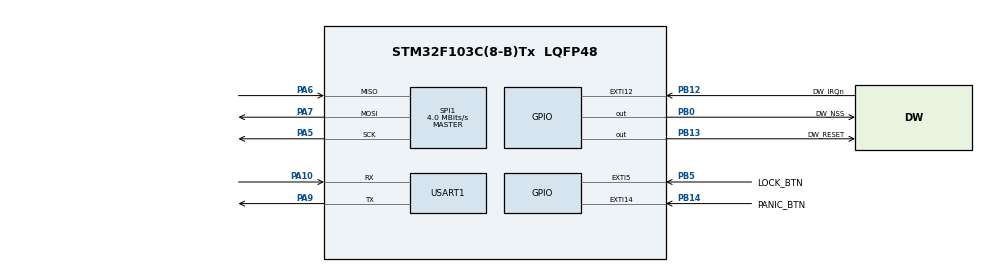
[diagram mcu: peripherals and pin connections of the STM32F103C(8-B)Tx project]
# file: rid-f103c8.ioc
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Mcu.Family=STM32F1
Mcu.Name=STM32F103C(8-B)Tx
Mcu.Package=LQFP48
NVIC.EXTI15_10_IRQn=true\:0\:0\:false\:false\:true\:true\:true\:true
NVIC.EXTI9_5_IRQn=true\:0\:0\:false\:false\:true\:true\:true\:true
NVIC.PriorityGroup=NVIC_PRIORITYGROUP_4
PA10.Mode=Asynchronous
PA10.Signal=USART1_RX
PA13.Mode=Serial_Wire
PA13.Signal=SYS_JTMS-SWDIO
PA14.Mode=Serial_Wire
PA14.Signal=SYS_JTCK-SWCLK
PA5.Mode=Full_Duplex_Master
PA5.Signal=SPI1_SCK
PA6.Mode=Full_Duplex_Master
PA6.Signal=SPI1_MISO
PA7.Mode=Full_Duplex_Master
PA7.Signal=SPI1_MOSI
PA9.Mode=Asynchronous
PA9.Signal=USART1_TX
PB0.GPIO_Label=DW_NSS
PB0.PinState=GPIO_PIN_SET
PB0.Signal=GPIO_Output
PB12.GPIO_Label=DW_IRQn
PB12.GPIO_PuPd=GPIO_PULLDOWN
PB12.Signal=GPXTI12
PB13.GPIO_Label=DW_RESET
PB13.GPIO_ModeDefaultOutputPP=GPIO_MODE_OUTPUT_OD
PB13.GPIO_PuPd=GPIO_NOPULL
PB13.Signal=GPIO_Output
PB14.GPIO_Label=PANIC_BTN
PB14.GPIO_ModeDefaultEXTI=GPIO_MODE_IT_FALLING
PB14.GPIO_PuPd=GPIO_PULLUP
PB14.Signal=GPXTI14
PB5.GPIO_Label=LOCK_BTN
PB5.GPIO_ModeDefaultEXTI=GPIO_MODE_IT_FALLING
PB5.GPIO_PuPd=GPIO_PULLUP
PB5.Signal=GPXTI5
ProjectManager.HeapSize=0x200
ProjectManager.StackSize=0x400
ProjectManager.TargetToolchain=STM32CubeIDE
RCC.APB1Freq_Value=8000000
RCC.APB2Freq_Value=8000000
SPI1.CalculateBaudRate=4.0 MBits/s
SPI1.Direction=SPI_DIRECTION_2LINES
SPI1.Mode=SPI_MODE_MASTER
SPI1.VirtualType=VM_MASTER
USART1.VirtualMode=VM_ASYNC
board=custom

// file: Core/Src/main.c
/* USER CODE BEGIN Header */
/**
  ******************************************************************************
  * @file           : main.c
  * @brief          : Main program body
  ******************************************************************************
  * @attention
  *
  * Copyright (c) 2022 STMicroelectronics.
  * All rights reserved.
  *
  * This software is licensed under terms that can be found in the LICENSE file
  * in the root directory of this software component.
  * If no LICENSE file comes with this software, it is provided AS-IS.
  *
  ******************************************************************************
  */
/* USER CODE END Header */
#include "main.h"

/* USER CODE BEGIN Includes */
#include "stdio_d.h"
#include "rid.h"

#include "deca_device_api.h"

//#include "ex_01a_simple_tx/ex_01a_main.c"
/* USER CODE END Includes */

SPI_HandleTypeDef hspi1;

UART_HandleTypeDef huart1;

void SystemClock_Config(void);
static void MX_GPIO_Init(void);
static void MX_SPI1_Init(void);
static void MX_USART1_UART_Init(void);

int main(void)
{

  /* MCU Configuration--------------------------------------------------------*/

  /* Reset of all peripherals, Initializes the Flash interface and the Systick. */
  HAL_Init();

  /* Configure the system clock */
  SystemClock_Config();

  /* Initialize all configured peripherals */
  MX_GPIO_Init();
  MX_SPI1_Init();
  MX_USART1_UART_Init();
  /* USER CODE BEGIN 2 */
  stdio_init(&huart1);
  rid_main();
  //  dw_main();
  /* USER CODE END 2 */

  /* Infinite loop */
  /* USER CODE BEGIN WHILE */
  while (1)
  {
		stdio_write("\r\nstarting RID\r\n");
	    uint32 devid = dwt_readdevid();
	    HAL_Delay(100);
    /* USER CODE END WHILE */

  }
}

void SystemClock_Config(void)
{
  RCC_OscInitTypeDef RCC_OscInitStruct = {0};
  RCC_ClkInitTypeDef RCC_ClkInitStruct = {0};

  /** Initializes the RCC Oscillators according to the specified parameters
  * in the RCC_OscInitTypeDef structure.
  */
  RCC_OscInitStruct.OscillatorType = RCC_OSCILLATORTYPE_HSI;
  RCC_OscInitStruct.HSIState = RCC_HSI_ON;
  RCC_OscInitStruct.HSICalibrationValue = RCC_HSICALIBRATION_DEFAULT;
  RCC_OscInitStruct.PLL.PLLState = RCC_PLL_NONE;
  if (HAL_RCC_OscConfig(&RCC_OscInitStruct) != HAL_OK)
  {
    Error_Handler();
  }

  /** Initializes the CPU, AHB and APB buses clocks
  */
  RCC_ClkInitStruct.ClockType = RCC_CLOCKTYPE_HCLK|RCC_CLOCKTYPE_SYSCLK
                              |RCC_CLOCKTYPE_PCLK1|RCC_CLOCKTYPE_PCLK2;
  RCC_ClkInitStruct.SYSCLKSource = RCC_SYSCLKSOURCE_HSI;
  RCC_ClkInitStruct.AHBCLKDivider = RCC_SYSCLK_DIV1;
  RCC_ClkInitStruct.APB1CLKDivider = RCC_HCLK_DIV1;
  RCC_ClkInitStruct.APB2CLKDivider = RCC_HCLK_DIV1;

  if (HAL_RCC_ClockConfig(&RCC_ClkInitStruct, FLASH_LATENCY_0) != HAL_OK)
  {
    Error_Handler();
  }
}

static void MX_SPI1_Init(void)
{

  /* SPI1 parameter configuration*/
  hspi1.Instance = SPI1;
  hspi1.Init.Mode = SPI_MODE_MASTER;
  hspi1.Init.Direction = SPI_DIRECTION_2LINES;
  hspi1.Init.DataSize = SPI_DATASIZE_8BIT;
  hspi1.Init.CLKPolarity = SPI_POLARITY_LOW;
  hspi1.Init.CLKPhase = SPI_PHASE_1EDGE;
  hspi1.Init.NSS = SPI_NSS_SOFT;
  hspi1.Init.BaudRatePrescaler = SPI_BAUDRATEPRESCALER_2;
  hspi1.Init.FirstBit = SPI_FIRSTBIT_MSB;
  hspi1.Init.TIMode = SPI_TIMODE_DISABLE;
  hspi1.Init.CRCCalculation = SPI_CRCCALCULATION_DISABLE;
  hspi1.Init.CRCPolynomial = 10;
  if (HAL_SPI_Init(&hspi1) != HAL_OK)
  {
    Error_Handler();
  }

}

static void MX_USART1_UART_Init(void)
{

  huart1.Instance = USART1;
  huart1.Init.BaudRate = 115200;
  huart1.Init.WordLength = UART_WORDLENGTH_8B;
  huart1.Init.StopBits = UART_STOPBITS_1;
  huart1.Init.Parity = UART_PARITY_NONE;
  huart1.Init.Mode = UART_MODE_TX_RX;
  huart1.Init.HwFlowCtl = UART_HWCONTROL_NONE;
  huart1.Init.OverSampling = UART_OVERSAMPLING_16;
  if (HAL_UART_Init(&huart1) != HAL_OK)
  {
    Error_Handler();
  }

}

static void MX_GPIO_Init(void)
{
  GPIO_InitTypeDef GPIO_InitStruct = {0};

  /* GPIO Ports Clock Enable */
  __HAL_RCC_GPIOA_CLK_ENABLE();
  __HAL_RCC_GPIOB_CLK_ENABLE();

  /*Configure GPIO pin Output Level */
  HAL_GPIO_WritePin(DW_NSS_GPIO_Port, DW_NSS_Pin, GPIO_PIN_SET);

  /*Configure GPIO pin Output Level */
  HAL_GPIO_WritePin(DW_RESET_GPIO_Port, DW_RESET_Pin, GPIO_PIN_RESET);

  /*Configure GPIO pin : DW_NSS_Pin */
  GPIO_InitStruct.Pin = DW_NSS_Pin;
  GPIO_InitStruct.Mode = GPIO_MODE_OUTPUT_PP;
  GPIO_InitStruct.Pull = GPIO_NOPULL;
  GPIO_InitStruct.Speed = GPIO_SPEED_FREQ_LOW;
  HAL_GPIO_Init(DW_NSS_GPIO_Port, &GPIO_InitStruct);

  /*Configure GPIO pin : DW_IRQn_Pin */
  GPIO_InitStruct.Pin = DW_IRQn_Pin;
  GPIO_InitStruct.Mode = GPIO_MODE_IT_RISING;
  GPIO_InitStruct.Pull = GPIO_PULLDOWN;
  HAL_GPIO_Init(DW_IRQn_GPIO_Port, &GPIO_InitStruct);

  /*Configure GPIO pin : DW_RESET_Pin */
  GPIO_InitStruct.Pin = DW_RESET_Pin;
  GPIO_InitStruct.Mode = GPIO_MODE_OUTPUT_OD;
  GPIO_InitStruct.Pull = GPIO_NOPULL;
  GPIO_InitStruct.Speed = GPIO_SPEED_FREQ_LOW;
  HAL_GPIO_Init(DW_RESET_GPIO_Port, &GPIO_InitStruct);

  /*Configure GPIO pins : PANIC_BTN_Pin LOCK_BTN_Pin */
  GPIO_InitStruct.Pin = PANIC_BTN_Pin|LOCK_BTN_Pin;
  GPIO_InitStruct.Mode = GPIO_MODE_IT_FALLING;
  GPIO_InitStruct.Pull = GPIO_PULLUP;
  HAL_GPIO_Init(GPIOB, &GPIO_InitStruct);

  /* EXTI interrupt init*/
  HAL_NVIC_SetPriority(EXTI9_5_IRQn, 0, 0);
  HAL_NVIC_EnableIRQ(EXTI9_5_IRQn);

  HAL_NVIC_SetPriority(EXTI15_10_IRQn, 0, 0);
  HAL_NVIC_EnableIRQ(EXTI15_10_IRQn);

}

void Error_Handler(void)
{
  __disable_irq();
  while (1)
  {
  }
}
